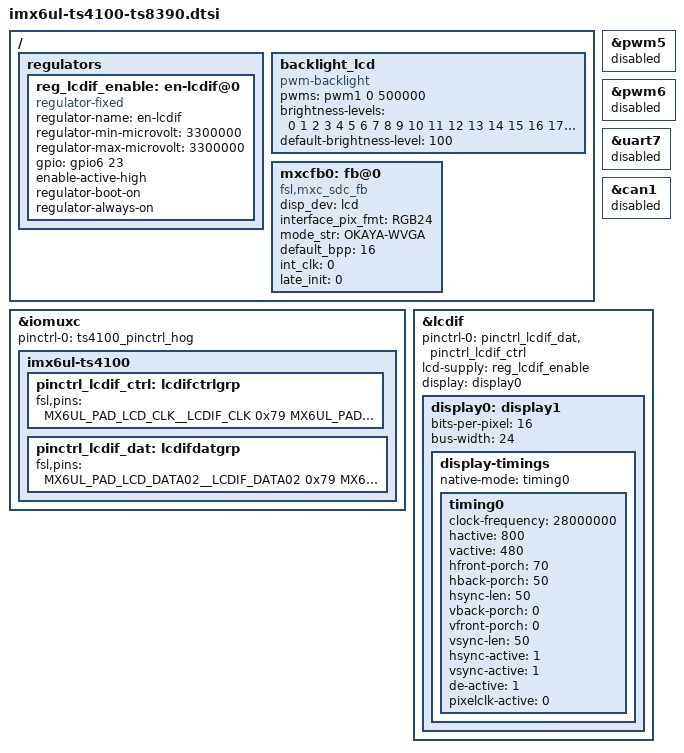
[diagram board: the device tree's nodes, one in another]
/*
 * Copyright (C) 2016-2022 Technologic Systems, Inc. dba embeddedTS
 *
 * This program is free software; you can redistribute it and/or modify
 * it under the terms of the GNU General Public License version 2 as
 * published by the Free Software Foundation.
 */

/*
 * Note that this combination of devices is not officially supported
 * at this time. This however can be used as-is or as a testbed for
 * adding other LCD support to the TS-4100
 */

#include <dt-bindings/input/input.h>

/ {

	regulators {
		reg_lcdif_enable: en-lcdif@0 {
			compatible = "regulator-fixed";
			regulator-name = "en-lcdif";
			regulator-min-microvolt = <3300000>;
			regulator-max-microvolt = <3300000>;
			gpio = <&gpio6 23 GPIO_ACTIVE_HIGH>;
			enable-active-high;
			/* The mxsfb driver doesn't properly handle an
			 * EPROBE_DEFER from trying to get the gpio for power
			 * control. Because of this, just force the regulator
			 * on from the kernel as soon as it can be turned on.
			 */
			regulator-boot-on;
			regulator-always-on;
		};
	};

	backlight_lcd {
		compatible = "pwm-backlight";
		pwms = <&pwm1 0 500000>;
		brightness-levels = < 0  1  2  3  4  5  6  7  8  9
		 10 11 12 13 14 15 16 17 18 19
		 20 21 22 23 24 25 26 27 28 29
		 30 31 32 33 34 35 36 37 38 39
		 40 41 42 43 44 45 46 47 48 49
		 50 51 52 53 54 55 56 57 58 59
		 60 61 62 63 64 65 66 67 68 69
		 70 71 72 73 74 75 76 77 78 79
		 80 81 82 83 84 85 86 87 88 89
		 90 91 92 93 94 95 96 97 98 99
		 100>;

		default-brightness-level = <100>;
	};


	mxcfb0: fb@0 {
		compatible = "fsl,mxc_sdc_fb";
		disp_dev = "lcd";
		interface_pix_fmt = "RGB24";
		mode_str ="OKAYA-WVGA";
		default_bpp = <16>;
		int_clk = <0>;
		late_init = <0>;
		status = "okay";
	};

};

/* Conflicts with LCD DATA pins */
&pwm5 {
	status = "disabled";
};
&pwm6 {
	status = "disabled";
};
&uart7 {
	status = "disabled";
};
&can1 {
	status = "disabled";
};




&iomuxc {
	pinctrl-names = "default";
	pinctrl-0 = <&ts4100_pinctrl_hog>;
	imx6ul-ts4100 {
	
		pinctrl_lcdif_ctrl: lcdifctrlgrp {
			fsl,pins = <
				MX6UL_PAD_LCD_CLK__LCDIF_CLK	    0x79
				MX6UL_PAD_LCD_ENABLE__LCDIF_ENABLE  0x79
				MX6UL_PAD_LCD_HSYNC__LCDIF_HSYNC    0x79
				MX6UL_PAD_LCD_VSYNC__LCDIF_VSYNC    0x79				
			>;
		};

		pinctrl_lcdif_dat: lcdifdatgrp {
			fsl,pins = <				
				MX6UL_PAD_LCD_DATA02__LCDIF_DATA02  0x79
				MX6UL_PAD_LCD_DATA03__LCDIF_DATA03  0x79
				MX6UL_PAD_LCD_DATA04__LCDIF_DATA04  0x79
				MX6UL_PAD_LCD_DATA05__LCDIF_DATA05  0x79
				MX6UL_PAD_LCD_DATA06__LCDIF_DATA06  0x79
				MX6UL_PAD_LCD_DATA07__LCDIF_DATA07  0x79
				
				MX6UL_PAD_LCD_DATA10__LCDIF_DATA10  0x79
				MX6UL_PAD_LCD_DATA11__LCDIF_DATA11  0x79
				MX6UL_PAD_LCD_DATA12__LCDIF_DATA12  0x79
				MX6UL_PAD_LCD_DATA13__LCDIF_DATA13  0x79
				MX6UL_PAD_LCD_DATA14__LCDIF_DATA14  0x79
				MX6UL_PAD_LCD_DATA15__LCDIF_DATA15  0x79
				
				MX6UL_PAD_LCD_DATA18__LCDIF_DATA18  0x79
				MX6UL_PAD_LCD_DATA19__LCDIF_DATA19  0x79
				MX6UL_PAD_LCD_DATA20__LCDIF_DATA20  0x79
				MX6UL_PAD_LCD_DATA21__LCDIF_DATA21  0x79
				MX6UL_PAD_LCD_DATA22__LCDIF_DATA22  0x79
				MX6UL_PAD_LCD_DATA23__LCDIF_DATA23  0x79
			>;
		};

   };	
};


&lcdif {
	pinctrl-names = "default";
	pinctrl-0 = <&pinctrl_lcdif_dat
		     &pinctrl_lcdif_ctrl>;
	lcd-supply = <&reg_lcdif_enable>;
	display = <&display0>;
	status = "okay";

	display0: display1 {
		bits-per-pixel = <16>;
		bus-width = <24>;

		display-timings {
			native-mode = <&timing0>;
			timing0: timing0 {
			clock-frequency = <28000000>;
			hactive = <800>;
			vactive = <480>;
			hfront-porch = <70>;
			hback-porch = <50>;
			hsync-len = <50>;
			vback-porch = <0>;
			vfront-porch = <0>;
			vsync-len = <50>;

			hsync-active = <1>;
			vsync-active = <1>;
			de-active = <1>;
			pixelclk-active = <0>;
			};
		};
	};
};
